# nrf9120_modem register map
Vendor: Nordic Semiconductor; Series: nrf91; File version: 1
CPU: CM4 r0p1, little endian, MPU, FPU, 3 interrupt priority bits
Registers are 32-bit, read-write, reset 0x0 unless marked. A register's access mark holds for its fields unless they carry their own. Offsets are from the block's base; [hi:lo] are bit positions; lines under a group give offsets from that group; {n}, {i} and the like mark numbered series; 'fields as' and 'values as' point back to an identical list.

## AMLI_NS — AHB Multi-Layer Interface
Base 0x40000000
0xE00 RAMPRI group — RAM configurable priority configuration structure
  0x00 CPU — AHB bus master priority register for CPU
    [0] RAM_0 — Priority register for RAM AHB slaves
      0=Pri0 (Priority 0); 1=Pri1 (Priority 1)
  {0x4+4j} EXTRAM[{j}] (j=0..0) — Description collection: AHB bus master priority register for external RAM slave port (EXTRAMs)
    fields as RAMPRI.CPU

## DCNF_NS — Domain Configuration Management
Base 0x40000000; alternate view of AMLI_NS
0x420 CPUID ro reset 0x1 — CPU number in the system
  [7:0] CPUID
0x440 EXTPERI0 group — Unspecified
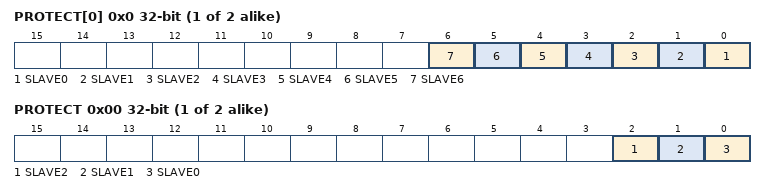
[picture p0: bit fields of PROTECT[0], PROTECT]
  {0x0+4j} PROTECT[{j}] (j=0..1) — Description collection: Control access for Master connected to AMLI master port EXTPERI[n]
    [all] fields
      0=Allowed (Access to slave is possible); 1=Blocked (Access to slave is blocked)
    [n] SLAVE{n} (n=0..6) — Control access to slave {n} of master EXTPERI[n].
0x460 EXTRAM group — Unspecified
  {0x0+4j} PROTECT[{j}] (j=0..1) — Description collection: Control access from Master connected to AMLI master port EXTRAM[n]
    [all] fields
      values as the fields of EXTPERI0.PROTECT[0]
    [n] SLAVE{n} (n=0..7) — Control access to slave {n} of master EXTRAM[n].
{0x480+4i} EXTCODE[{i}] (i=0..1) group — Unspecified
  0x00 PROTECT — Description cluster: Control access from Master connected to AMLI master port EXTCODE[n]
    [all] fields
      values as the fields of EXTPERI0.PROTECT[0]
    [2] SLAVE2 — Control access to slave 2 of master EXTCODE[n].
    [1] SLAVE1 — Control access to slave 1 of master EXTCODE[n].
    [0] SLAVE0 — Control access to slave 0 of master EXTCODE[n].
0x488 CSTNUMPRETICKS reset 0x5 — ClockStatusTracker pretick count setting
  [5:0] NUMPRETICKS — Pretick count setting.
0x48C CSTNUMPOSTTICKS reset 0x1 — ClockStatusTracker posttick count setting
  [5:0] NUMPOSTTICKS — Posttick count setting.

## TRACEANDDEBUG_NS — Trace And Debug
Base 0xE0080000
0x00 STARTCLOCKS wo — Start all Trace and Debug clocks.
  [0] STARTCLOCKS
    1=STARTCLOCKS (Start all Trace and Debug clocks.)
0x04 STOPCLOCKS wo — Stop all Trace and Debug clocks.
  [0] STOPCLOCKS
    1=STOPCLOCKS (Stop all Trace and Debug clocks.)
0x500 ENABLEDEBUG — Master enable for PSEL.TraceData[3:0] and PSEL.TraceClk signals
  [0] ENABLEDEBUG
    1=ENABLEDEBUG (Master enable for PSEL.TraceData[3:0] and PSEL.TraceClk signals)
0x504 PSEL group — Unspecified
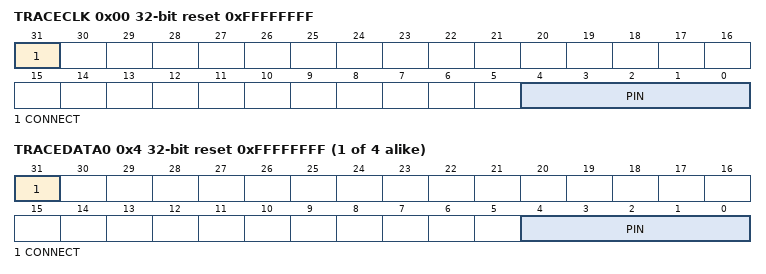
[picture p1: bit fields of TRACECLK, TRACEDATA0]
  0x00 TRACECLK reset 0xFFFFFFFF — Pin number configuration for TraceClk signal
    [31] CONNECT — Connection
      1=Disconnected; 0=Connected
    [4:0] PIN — Pin number
  {0x4+4j} TRACEDATA{j} reset 0xFFFFFFFF (j=0..3) — Pin number configuration for TraceData{j} signal
    fields as PSEL.TRACECLK
0x518 TRACEPORTSPEED — Trace port speed selection
  [1:0] TRACEPORTSPEED — Speed of Trace Port clock. Note that the TRACECLK pin will output this clock divided by two.
    0=32 MHz Trace Port clock (TRACECLK = 16 MHz); 1=16 MHz Trace Port clock (TRACECLK = 8 MHz); 2=8 MHz Trace Port clock (TRACECLK = 4 MHz); 3=4 MHz Trace Port clock (TRACECLK = 2 MHz)
0x51C SWOSEL — Connect the SWO to the TPIU TRACEDATA[0]
  [0] SWOSEL
    0=TRACEDATA0SEL (Connect the TRACEDATA[0] to the TPIU TRACEDATA[0]); 1=SWOSEL (Connect the SWO to the TPIU TRACEDATA[0])

## BBPLL_NS — Base Band PLL
Base 0x40011000
0x500 FREQ reset 0x2 — Frequency selection
  [2:0] FREQ
    0=128 MHz; 1=144 MHz; 2=160 MHz (default); 3=176 MHz; 4=192 MHz

## TIMER1_NS — Modem Timer/Counter 0
Base 0x40024000
Same registers: TIMER0_NS 0x40056000
0x00 TASKS_START wo — Start Timer
  [0] TASKS_START
    1=Trigger task
0x04 TASKS_STOP wo — Stop Timer
  [0] TASKS_STOP
    1=Trigger task
0x08 TASKS_CLEAR wo — Clear time
  [0] TASKS_CLEAR
    1=Trigger task
0x0C TASKS_SHUTDOWN wo — Shut down timer
  [0] TASKS_SHUTDOWN
    1=Trigger task
0x10 TASKS_STANDBY wo — Timer from shutdown to stopped state
  [0] TASKS_STANDBY
    1=Trigger task
{0x40+4i} TASKS_CAPTURE[{i}] (i=0..7) wo — Description collection: Capture Timer value to CC[n] register
  [0] TASKS_CAPTURE — Capture Timer value to CC[n] register
    1=Trigger task
{0x100+4i} EVENTS_COMPARE[{i}] (i=0..7) — Description collection: Compare event on CC[n] match.
  [0] EVENTS_COMPARE — Compare event on CC[n] match.
    0=NotGenerated (Event not generated); 1=Generated (Event generated)
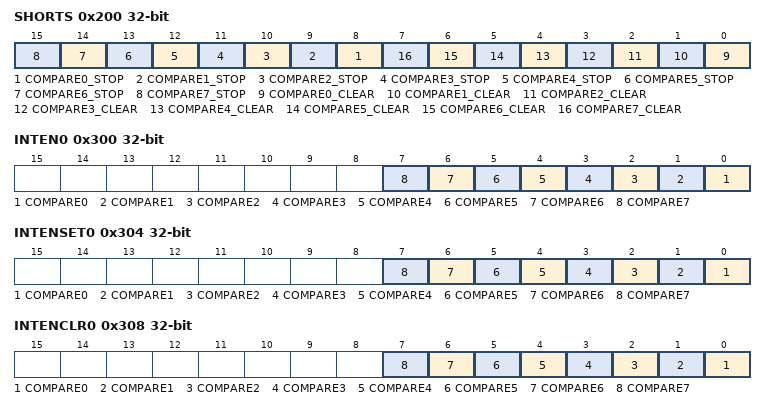
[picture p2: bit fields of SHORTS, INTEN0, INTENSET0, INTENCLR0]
0x200 SHORTS — Shortcuts between local events and tasks
  [all] fields
    0=Disabled (Disable shortcut); 1=Enabled (Enable shortcut)
  [n+8] COMPARE{n}_STOP (n=0..7) — Shortcut between event COMPARE[{n}] and task STOP
  [n] COMPARE{n}_CLEAR (n=0..7) — Shortcut between event COMPARE[{n}] and task CLEAR
0x300 INTEN0 — Enable or disable interrupt
  [all] fields
    0=Disabled; 1=Enabled
  [n] COMPARE{n} (n=0..7) — Enable or disable interrupt for event COMPARE[{n}]
0x304 INTENSET0 — Enable interrupt
  [all] fields
    on read: 0=Disabled (Read: Disabled); 1=Enabled (Read: Enabled) | on write: 1=Set (Enable)
  [n] COMPARE{n} (n=0..7) — Write '1' to enable interrupt for event COMPARE[{n}]
0x308 INTENCLR0 — Disable interrupt
  [all] fields
    on read: 0=Disabled (Read: Disabled); 1=Enabled (Read: Enabled) | on write: 1=Clear (Disable)
  [n] COMPARE{n} (n=0..7) — Write '1' to disable interrupt for event COMPARE[{n}]
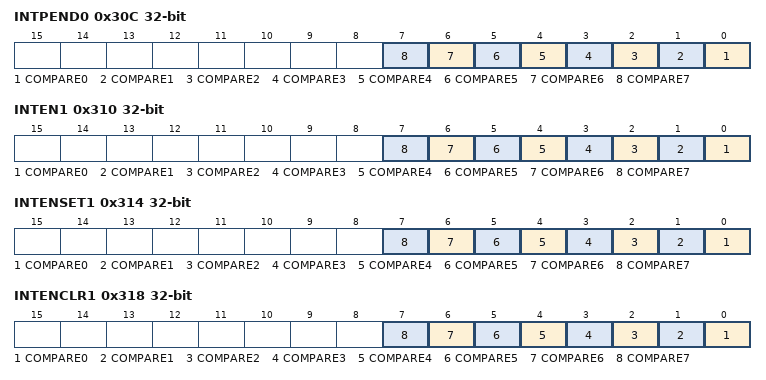
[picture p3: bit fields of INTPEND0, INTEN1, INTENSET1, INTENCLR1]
0x30C INTPEND0 ro — Pending interrupts
  [all] fields
    on read: 0=NotPending (Read: Not pending); 1=Pending (Read: Pending)
  [n] COMPARE{n} (n=0..7) — Read pending status of interrupt for event COMPARE[{n}]
0x310 INTEN1 — Enable or disable interrupt
  fields as INTEN0
0x314 INTENSET1 — Enable interrupt
  fields as INTENSET0
0x318 INTENCLR1 — Disable interrupt
  fields as INTENCLR0
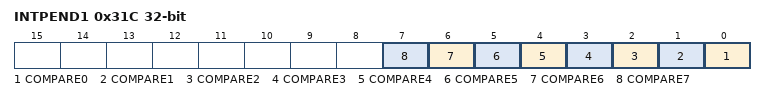
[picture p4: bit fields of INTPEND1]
0x31C INTPEND1 ro — Pending interrupts
  fields as INTPEND0
0x504 RUNNING — Status of running timer
  [1:0] STATUS — Current status
    0=SHUTDOWN (Timer is powered off.); 1=RUNNING (Timer is actively running.); 2=STOPPED (Timer is stopped.)
{0x540+8i} CCLO{i} (i=0..7) — Capture/Compare register {i} - Low Word
  [31:0] CCLO — Capture/Compare value Low Word
{0x544+8i} CCHI{i} (i=0..7) — Capture/Compare register {i} - High Word
  [31:0] CCHI — Capture/Compare value High Word
0x580 COUNTLO — Internal Counter Value - Low Word
0x584 COUNTHI — Internal Counter Value - High Word
  [31:0] COUNTHI — Internal Counter Value High Word
0xFFC POWER reset 0x1 — Peripheral power control
  [0] POWER — Peripheral power control. The peripheral and its registers will be reset to its initial state by switching the peripheral off and then back on again.
    0=Disabled (Peripheral is powered off); 1=Enabled (Peripheral is powered on)
